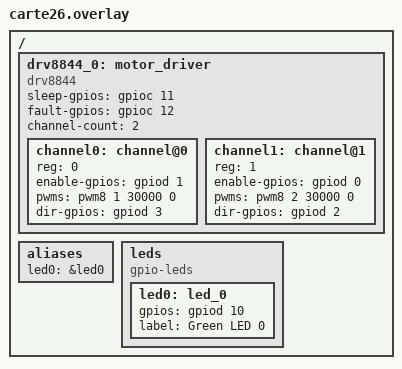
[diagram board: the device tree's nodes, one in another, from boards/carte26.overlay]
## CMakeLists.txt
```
cmake_minimum_required(VERSION 3.13.0)

if (NOT DEFINED BOARD)
    set(BOARD board_2026)
endif ()

find_package(Zephyr REQUIRED HINTS $ENV{ZEPHYR_BASE})

project(app LANGUAGES C CXX)

target_sources(app PRIVATE src/main.c)
```

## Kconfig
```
# SPDX-License-Identifier: AGPL-3.0

menu "Zephyr"
source "Kconfig.zephyr"
endmenu

menu "Application"


    menu "threads"
    menu "stacks"
        config DEFAULT_THREAD_STACK_SIZE
            int "Default thread stack size"
            default 512
            help
                This option sets the default thread stack size for the application.

        config IHM_THREAD_STACK_SIZE
            int "IHM thread stack size"
            default DEFAULT_THREAD_STACK_SIZE
            help
                This option sets the IHM thread stack size for the application.

        config SENSOR_THREAD_STACK_SIZE
            int "Sensor thread stack size"
            default DEFAULT_THREAD_STACK_SIZE
            help
                This option sets the Sensor thread stack size for the application.

        config MOTOR_THREAD_STACK_SIZE
            int "Motor thread stack size"
            default DEFAULT_THREAD_STACK_SIZE
            help
                This option sets the Motor thread stack size for the application.
    endmenu
    menu "priorities"
        config DEFAULT_THREAD_PRIORITY
            int "Default thread priority"
            default 5
            help
                This option sets the default thread priority for the application.


        config IHM_THREAD_PRIORITY
            int "IHM thread priority"
            default DEFAULT_THREAD_PRIORITY
            help
                This option sets the IHM thread priority for the application.

        config SENSOR_THREAD_PRIORITY
            int "Sensor thread priority"
            default DEFAULT_THREAD_PRIORITY
            help
                This option sets the Sensor thread priority for the application.

        config MOTOR_THREAD_PRIORITY
            int "Motor thread priority"
            default DEFAULT_THREAD_PRIORITY
            help
                This option sets the Motor thread priority for the application.
        endmenu
    endmenu

endmenu

module = APP
module-str = APP
source "subsys/logging/Kconfig.template.log_config"
```

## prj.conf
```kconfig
# --- Misc / app ---
CONFIG_GPIO=y
CONFIG_PWM=y
CONFIG_SENSOR=y
# Required in order to boot the beacon sensor
CONFIG_MAIN_STACK_SIZE=2048
CONFIG_BEACON_SENSOR=y

# --- Logging ---
CONFIG_LOG=y
CONFIG_LOG_INFO_COLOR_GREEN=y
CONFIG_LOG_MODE_DEFERRED=y
CONFIG_LOG_BUFFER_SIZE=4096
CONFIG_LOG_DEFAULT_LEVEL=2
CONFIG_ESP_HOSTED_MCU_LOG_LEVEL_ERR=y
CONFIG_NET_LOG=n

# Print floats
CONFIG_CBPRINTF_FP_SUPPORT=y

# --- Wi-Fi ---
CONFIG_WIFI=y
CONFIG_WIFI_ESP_HOSTED_MCU=y
CONFIG_ESP_HOSTED_MCU_FW_VERSION_MAJOR=3

# --- Networking ---
CONFIG_NETWORKING=y
CONFIG_NET_IPV4=y
CONFIG_NET_IPV6=n
CONFIG_NET_UDP=y
CONFIG_NET_TCP=y
CONFIG_NET_DHCPV4=y
CONFIG_NET_SOCKETS=y
CONFIG_NET_SOCKETS_SERVICE_THREAD_PRIO=-1
CONFIG_ZVFS_POLL_MAX=9
CONFIG_NET_MAX_CONTEXTS=5
CONFIG_NET_IF_UNICAST_IPV4_ADDR_COUNT=1
CONFIG_NET_TC_TX_COUNT=1

CONFIG_NET_PKT_RX_COUNT=40
CONFIG_NET_PKT_TX_COUNT=40
CONFIG_NET_BUF_RX_COUNT=160
CONFIG_NET_BUF_TX_COUNT=160
CONFIG_NET_BUF_DATA_SIZE=512

# --- Test tooling ---
CONFIG_SHELL=y
CONFIG_SHELL_CMDS_RESIZE=n
CONFIG_NET_SHELL=y
CONFIG_NET_L2_WIFI_SHELL=y
CONFIG_NET_ZPERF=y
CONFIG_NET_ZPERF_SERVER=y
CONFIG_NET_STATISTICS=n

# --- Performance ---
CONFIG_CACHE_MANAGEMENT=y
CONFIG_SPEED_OPTIMIZATIONS=y
CONFIG_TIMESLICING=n
CONFIG_INIT_STACKS=n
```

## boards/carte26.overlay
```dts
/*
	Created by Awing on the 22/10/2026
	SPDX-License-Identifier: AGPL-3.0
*/

/ {

	drv8844_0: motor_driver {
		compatible = "drv8844";
		status = "okay";

		#address-cells = <1>;
		#size-cells = <0>;

		sleep-gpios = <&gpioc 11 GPIO_ACTIVE_HIGH>;
		fault-gpios = <&gpioc 12 GPIO_ACTIVE_HIGH>;

		channel-count = <2>;

		channel0: channel@0 {
			reg = <0>;
			enable-gpios = <&gpiod 1 GPIO_ACTIVE_HIGH>;
			pwms = <&pwm8 1 30000 0>;
			dir-gpios = <&gpiod 3 GPIO_ACTIVE_HIGH>;
		};

		channel1: channel@1 {
			reg = <1>;
			enable-gpios = <&gpiod 0 GPIO_ACTIVE_HIGH>;
			pwms = <&pwm8 2 30000 0>;
			dir-gpios = <&gpiod 2 GPIO_ACTIVE_HIGH>;
		};

	};

	aliases {
		led0 = &led0;
	};

	leds {
		compatible = "gpio-leds";

		led0: led_0 {
			gpios = <&gpiod 10 GPIO_ACTIVE_HIGH>;
			label = "Green LED 0";
		};
	};

};
```

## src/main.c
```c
#include <zephyr/device.h>
#include <zephyr/devicetree.h>
#include <zephyr/drivers/gpio.h>
#include <zephyr/drivers/pwm.h>
#include <zephyr/drivers/sensor.h>
#include <zephyr/kernel.h>
#include <zephyr/logging/log.h>
#include <zephyr/sys/printk.h>

LOG_MODULE_REGISTER(main, LOG_LEVEL_INF);

#define LED0_NODE DT_ALIAS(led0)

static const struct gpio_dt_spec led = GPIO_DT_SPEC_GET(LED0_NODE, gpios);

static const struct device* lidar = DEVICE_DT_GET(DT_ALIAS(lidar));

static const struct device* const qright = DEVICE_DT_GET(DT_ALIAS(right_encoder));
static const struct device* const qleft = DEVICE_DT_GET(DT_ALIAS(left_encoder));

int main(void) {
    int ret;

    if (!device_is_ready(led.port)) {
        return -1;
    }

    if (!device_is_ready(lidar)) {
        LOG_ERR_DEVICE_NOT_READY(lidar);
        return -1;
    }

    ret = gpio_pin_configure_dt(&led, GPIO_OUTPUT_ACTIVE);
    if (ret < 0) {
        return -1;
    }

    struct sensor_value result;
    uint16_t distance;
    float angle;

    while (1) {
        ret = gpio_pin_toggle_dt(&led);
        if (ret < 0) {
            return 0;
        }

        k_msleep(20);

        struct sensor_value v;
        int32_t counts;

        sensor_sample_fetch(qright);
        sensor_channel_get(qright, SENSOR_CHAN_ENCODER_COUNT, &v);
        counts = v.val1;

        sensor_channel_get(qright, SENSOR_CHAN_ROTATION, &v);
        float rotation = sensor_value_to_float(&v);

        printk("TIM23: %d  %f\n", counts, rotation);

        if (sensor_sample_fetch(lidar) != 0) {
            LOG_INF("No sensor data available");
        } else {
            uint8_t status = sensor_channel_get(lidar, SENSOR_CHAN_DISTANCE, &result);
            distance = result.val1;

            status = sensor_channel_get(lidar, SENSOR_CHAN_ROTATION, &result);
            angle = sensor_value_to_float(&result);

            printk("Result from the sensor : %d mm %f rad \r\n", distance, angle);
        }
    }
}
```

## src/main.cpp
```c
//
// Created by awing on 11/20/26.
// SPDX-License-Identifier: AGPL-3.0
//

#include "zephyr/kernel.h"
#include "zephyr/logging/log.h"

#define THREAD_STACK_SIZE 512
#define DEFAULT_PRIORITY 5

LOG_MODULE_REGISTER(main, LOG_LEVEL_INF);

K_MSGQ_DEFINE(ihm_queue, sizeof(char[100]), 20, 1);

static void dummy(void* ihm_queue_tag,void*,void*){}

K_THREAD_DEFINE(ihm_thread, CONFIG_IHM_THREAD_STACK_SIZE, dummy, &ihm_queue, NULL, NULL, CONFIG_IHM_THREAD_PRIORITY, 0, -1);
K_THREAD_DEFINE(motor_thread, CONFIG_MOTOR_THREAD_STACK_SIZE, dummy, &ihm_queue, NULL, NULL, CONFIG_MOTOR_THREAD_PRIORITY, 0, -1);
K_THREAD_DEFINE(sensor_thread, CONFIG_SENSOR_THREAD_STACK_SIZE, dummy, &ihm_queue, NULL, NULL, CONFIG_SENSOR_THREAD_PRIORITY, 0, -1);

int main() {



    k_sched_lock();
    k_thread_start(ihm_thread);
    k_thread_start(motor_thread);
    k_thread_start(sensor_thread);
    k_sched_unlock();

    while (true) {
        
        k_yield();
    }
}
```

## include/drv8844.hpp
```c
#pragma once

#include <zephyr/drivers/gpio.h>
#include <zephyr/drivers/pwm.h>

struct Drv8844Motor {
    pwm_dt_spec enable;
    gpio_dt_spec input_a;
    gpio_dt_spec input_b;
};

class Drv8844 {
public:
    Drv8844(const Drv8844Motor& left, const Drv8844Motor& right,
            const gpio_dt_spec& reset, const gpio_dt_spec& fault);

    int init();
    int setVelocity(float left, float right);
    int stop();
    int readFault(bool& faulted) const;

private:
    int setMotor(const Drv8844Motor& motor, float velocity);

    Drv8844Motor left_;
    Drv8844Motor right_;
    gpio_dt_spec reset_;
    gpio_dt_spec fault_;
};
```

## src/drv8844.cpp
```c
#include "drv8844.hpp"

#include <errno.h>

#include <zephyr/device.h>
#include <zephyr/kernel.h>

namespace {
constexpr uint32_t kPwmPeriod = PWM_USEC(50);

bool gpioReady(const gpio_dt_spec& gpio)
{
    return gpio.port != nullptr && device_is_ready(gpio.port);
}
} // namespace

Drv8844::Drv8844(const Drv8844Motor& left, const Drv8844Motor& right,
                 const gpio_dt_spec& reset, const gpio_dt_spec& fault)
    : left_(left), right_(right), reset_(reset), fault_(fault)
{
}

int Drv8844::init()
{
    if (!device_is_ready(left_.enable.dev) ||
        !device_is_ready(right_.enable.dev) ||
        !gpioReady(left_.input_a) || !gpioReady(left_.input_b) ||
        !gpioReady(right_.input_a) || !gpioReady(right_.input_b) ||
        !gpioReady(reset_) || !gpioReady(fault_)) {
        return -ENODEV;
    }

    int ret = gpio_pin_configure_dt(&reset_, GPIO_OUTPUT_ACTIVE);
    if (ret != 0) {
        return ret;
    }

    const Drv8844Motor* motors[] = {&left_, &right_};
    for (const Drv8844Motor* motor : motors) {
        ret = gpio_pin_configure_dt(&motor->input_a, GPIO_OUTPUT_INACTIVE);
        if (ret != 0) {
            return ret;
        }
        ret = gpio_pin_configure_dt(&motor->input_b, GPIO_OUTPUT_INACTIVE);
        if (ret != 0) {
            return ret;
        }
        ret = pwm_set_dt(&motor->enable, kPwmPeriod, 0);
        if (ret != 0) {
            return ret;
        }
    }

    ret = gpio_pin_configure_dt(&fault_, GPIO_INPUT);
    if (ret != 0) {
        return ret;
    }

    return gpio_pin_set_dt(&reset_, 0);
}

int Drv8844::setVelocity(float left, float right)
{
    int ret = setMotor(left_, left);
    if (ret != 0) {
        int stop_ret = stop();
        return stop_ret != 0 ? stop_ret : ret;
    }

    ret = setMotor(right_, right);
    if (ret != 0) {
        int stop_ret = stop();
        return stop_ret != 0 ? stop_ret : ret;
    }
    return ret;
}

int Drv8844::stop()
{
    int left_ret = pwm_set_dt(&left_.enable, kPwmPeriod, 0);
    int right_ret = pwm_set_dt(&right_.enable, kPwmPeriod, 0);
    int left_a_ret = gpio_pin_set_dt(&left_.input_a, 0);
    int left_b_ret = gpio_pin_set_dt(&left_.input_b, 0);
    int right_a_ret = gpio_pin_set_dt(&right_.input_a, 0);
    int right_b_ret = gpio_pin_set_dt(&right_.input_b, 0);

    if (left_ret != 0) return left_ret;
    if (right_ret != 0) return right_ret;
    if (left_a_ret != 0) return left_a_ret;
    if (left_b_ret != 0) return left_b_ret;
    if (right_a_ret != 0) return right_a_ret;
    return right_b_ret;
}

int Drv8844::readFault(bool& faulted) const
{
    int value = gpio_pin_get_dt(&fault_);
    if (value < 0) {
        return value;
    }

    faulted = value != 0;
    return 0;
}

int Drv8844::setMotor(const Drv8844Motor& motor, float velocity)
{
    if (!(velocity >= -1.0f && velocity <= 1.0f)) {
        return -EINVAL;
    }

    float duty = velocity < 0.0f ? -velocity : velocity;
    uint32_t pulse = static_cast<uint32_t>(kPwmPeriod * duty);
    int ret = pwm_set_dt(&motor.enable, kPwmPeriod, 0);
    if (ret != 0) {
        return ret;
    }

    ret = gpio_pin_set_dt(&motor.input_a, velocity > 0.0f);
    if (ret != 0) {
        return ret;
    }
    ret = gpio_pin_set_dt(&motor.input_b, velocity < 0.0f);
    if (ret != 0) {
        return ret;
    }

    return pwm_set_dt(&motor.enable, kPwmPeriod, pulse);
}
```
